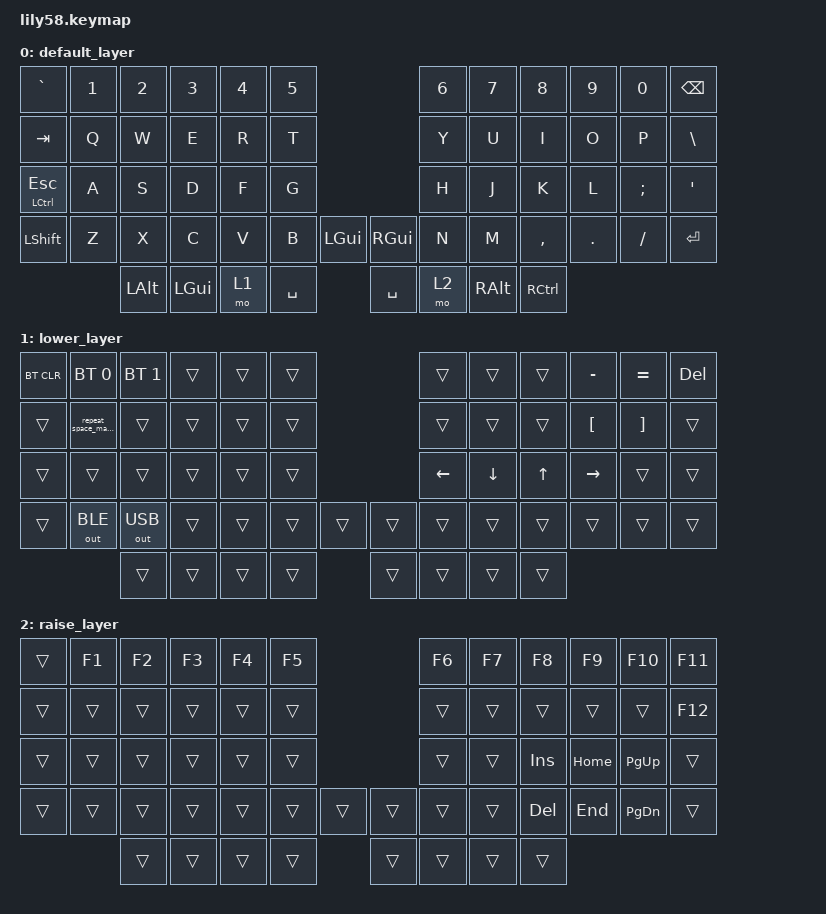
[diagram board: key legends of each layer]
/*
 * Copyright (c) 2020 The ZMK Contributors
 *
 * SPDX-License-Identifier: MIT
 */

#include <behaviors.dtsi>
#include <dt-bindings/zmk/keys.h>
#include <dt-bindings/zmk/bt.h>
#include <dt-bindings/zmk/ext_power.h>
#include <dt-bindings/zmk/outputs.h>

/ {
    behaviors {
        space_macro: space_macro {
            compatible = "zmk,behavior-macro";
            #binding-cells = <0>;
            wait-ms = <0>;
            tap-ms = <40>;
            bindings = <
                &macro_tap &kp N3
                &macro_wait_time 500
                &macro_tap &kp SPACE
                &macro_wait_time 500
            >;
        };

        repeat_space_macro: repeat_space_macro {
            compatible = "zmk,behavior-hold-tap";
            label = "REP_MACRO";
            #binding-cells = <2>;
            tapping-term-ms = <600>;
            quick-tap-ms = <0>;
            flavor = "tap-preferred";
            bindings = <&space_macro>, <&space_macro>;
        };
    };

    keymap {
        compatible = "zmk,keymap";

        default_layer {
// ------------------------------------------------------------------------------------------------------------
// |  `    |   1   |   2   |   3   |   4   |   5   |                  |   6   |   7   |   8   |   9   |   0   | BSPC  |
// |  TAB  |   Q   |   W   |   E   |   R   |   T   |                  |   Y   |   U   |   I   |   O   |   P   |   \   |
// |  ESC  |   A   |   S   |   D   |   F   |   G   |                  |   H   |   J   |   K   |   L   |   ;   |   '   |
// | SHIFT |   Z   |   X   |   C   |   V   |   B   |  LGUI |  |  RGUI |   N   |   M   |   ,   |   .   |   /   | ENTER |
//                     |  ALT |  LGUI  | LOWER | SPACE |          | SPACE | RAISE |  ALT  |  CTRL |
            bindings = <
&kp GRAVE     &kp N1        &kp N2        &kp N3        &kp N4        &kp N5                                &kp N6        &kp N7        &kp N8        &kp N9        &kp N0        &kp BSPC
&kp TAB       &kp Q         &kp W         &kp E         &kp R         &kp T                                 &kp Y         &kp U         &kp I         &kp O         &kp P         &kp BSLH
&mt LCTRL ESC &kp A         &kp S         &kp D         &kp F         &kp G                                 &kp H         &kp J         &kp K         &kp L         &kp SEMI      &kp SQT
&kp LSHFT     &kp Z         &kp X         &kp C         &kp V         &kp B         &kp LGUI  &kp RGUI      &kp N         &kp M         &kp COMMA     &kp DOT       &kp FSLH      &kp RET
                                   &kp LALT      &kp LGUI      &mo 1         &kp SPACE               &kp SPACE     &mo 2         &kp RALT      &kp RCTRL
            >;

            sensor-bindings = <&inc_dec_kp C_VOL_UP C_VOL_DN>;
        };

        lower_layer {
// ------------------------------------------------------------------------------------------------------------
// | BTCLR |  BT1  |  BT2  |       |       |       |                  |       |       |       |   -   |   +   |  DEL  |
// |       |       |       |       |       |       |                  |       |       |       |  "["  |  "]"  |       |
// |       |       |       |       |       |       |                  |  <-   |   v   |   ^   |  ->   |       |       |
// |       |  BLE  |  USB  |       |       |       |       |  |       |       |       |       |       |       |       |
//                     |       |       |       |       |          |       |       |       |       |
            bindings = <
&bt BT_CLR    &bt BT_SEL 0         &bt BT_SEL 1  &trans        &trans        &trans                                &trans        &trans        &trans        &kp MINUS     &kp EQUAL     &kp DEL
&trans        &repeat_space_macro  &trans        &trans        &trans        &trans                                &trans        &trans        &trans        &kp LBKT      &kp RBKT      &trans
&trans        &trans               &trans        &trans        &trans        &trans                                &kp LEFT      &kp DOWN      &kp UP        &kp RIGHT     &trans        &trans
&trans        &out OUT_BLE         &out OUT_USB  &trans        &trans        &trans        &trans    &trans        &trans        &trans        &trans        &trans        &trans        &trans 
                                          &trans        &trans        &trans        &trans                  &trans        &trans        &trans        &trans
            >;

            sensor-bindings = <&inc_dec_kp C_VOL_UP C_VOL_DN>;
        };

        raise_layer {
// ------------------------------------------------------------------------------------------------------------
// |       |  F1   |  F2   |  F3   |  F4   |  F5   |                  |  F6   |  F7   |  F8   |  F9   |  F10  |  F11  |
// |       |       |       |       |       |       |                  |       |       |       |       |       |  F12  |
// |       |       |       |       |       |       |                  |       |       |  INS  |  HOME | PG_UP |       |
// |       |       |       |       |       |       |       |  |       |       |       |  DEL  |  END  | PG_DN |       |
//                     |       |       |       |       |          |       |       |       |       |
            bindings = <
&trans        &kp F1        &kp F2        &kp F3        &kp F4        &kp F5                                &kp F6        &kp F7        &kp F8        &kp F9        &kp F10       &kp F11
&trans        &trans        &trans        &trans        &trans        &trans                                &trans        &trans        &trans        &trans        &trans        &kp F12
&trans        &trans        &trans        &trans        &trans        &trans                                &trans        &trans        &kp INS       &kp HOME      &kp PG_UP     &trans
&trans        &trans        &trans        &trans        &trans        &trans        &trans    &trans        &trans        &trans        &kp DEL       &kp END       &kp PG_DN     &trans
                                   &trans        &trans        &trans        &trans                  &trans        &trans        &trans        &trans
            >;

            sensor-bindings = <&inc_dec_kp C_VOL_UP C_VOL_DN>;
        };
    };
};
